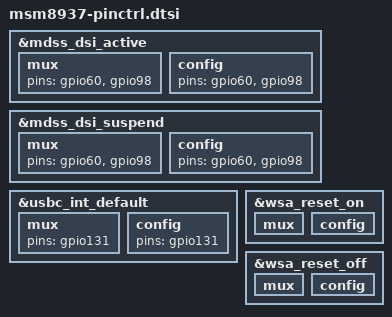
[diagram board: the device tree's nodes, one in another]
/*
 * Copyright (c) 2015-2018, The Linux Foundation. All rights reserved.
 *
 * This program is free software; you can redistribute it and/or modify
 * it under the terms of the GNU General Public License version 2 and
 * only version 2 as published by the Free Software Foundation.
 *
 * This program is distributed in the hope that it will be useful,
 * but WITHOUT ANY WARRANTY; without even the implied warranty of
 * MERCHANTABILITY or FITNESS FOR A PARTICULAR PURPOSE.  See the
 * GNU General Public License for more details.
 */

&mdss_dsi_active {
	mux {
		pins = "gpio60", "gpio98";
	};

	config {
		pins = "gpio60", "gpio98";
	};
};

&mdss_dsi_suspend {
	mux {
		pins = "gpio60", "gpio98";
	};

	config {
		pins = "gpio60", "gpio98";
	};
};

&usbc_int_default {
	mux {
		pins = "gpio131";
	};

	config {
		pins = "gpio131";
	};
};

&wsa_reset_on {
	mux {
		/delete-property/ pins;
	};

	config {
		/delete-property/ pins;
	};
};

&wsa_reset_off {
	mux {
		/delete-property/ pins;
	};

	config {
		/delete-property/ pins;
	};
};
